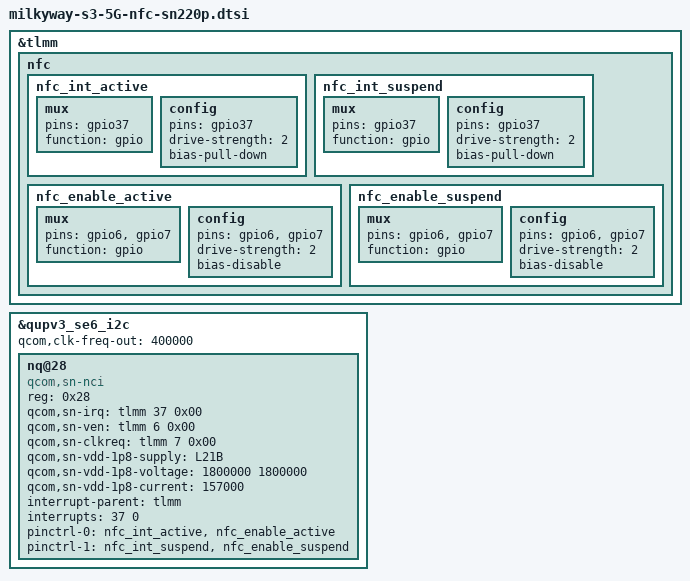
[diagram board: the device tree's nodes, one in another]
&tlmm {
	nfc {
		nfc_int_active: nfc_int_active {
			/* active state */
			mux {
				/* NFC Read Interrupt */
				pins = "gpio37";
				function = "gpio";
			};

			config {
				pins = "gpio37";
				drive-strength = <2>; /* 2 MA */
				bias-pull-down;
			};
		};

		nfc_int_suspend: nfc_int_suspend {
			/* sleep state */
			mux {
				/* NFC Read Interrupt */
				pins = "gpio37";
				function = "gpio";
			};

			config {
				pins = "gpio37";
				drive-strength = <2>; /* 2 MA */
				bias-pull-down;
			};
		};

		nfc_enable_active: nfc_enable_active {
			mux {
				/* Enable and Clock request gpios */
				pins = "gpio6", "gpio7";
				function = "gpio";
			};

			config {
				pins = "gpio6", "gpio7";
				drive-strength = <2>; /* 2 MA */
				bias-disable;
			};
		};

		nfc_enable_suspend: nfc_enable_suspend {
			mux {
				pins = "gpio6", "gpio7";
				function = "gpio";
			};

			config {
				pins = "gpio6", "gpio7";
				drive-strength = <2>; /* 2 MA */
				bias-disable;
			};
		};
	}; //nfc
}; //tlmm

&qupv3_se6_i2c {
	status = "ok";
	qcom,clk-freq-out = <400000>;
	#address-cells = <1>;
	#size-cells = <0>;
	nq@28 {
		compatible = "qcom,sn-nci";
		reg = <0x28>;
		qcom,sn-irq = <&tlmm 37 0x00>;
		qcom,sn-ven = <&tlmm 6 0x00>;
		qcom,sn-clkreq = <&tlmm 7 0x00>;
		qcom,sn-vdd-1p8-supply = <&L21B>;
		qcom,sn-vdd-1p8-voltage = <1800000 1800000>;
		qcom,sn-vdd-1p8-current = <157000>;
		interrupt-parent = <&tlmm>;
		interrupts = <37 0>;
		interrupt-names = "nfc_irq";
		pinctrl-names = "nfc_active", "nfc_suspend";
		pinctrl-0 = <&nfc_int_active &nfc_enable_active>;
		pinctrl-1 = <&nfc_int_suspend &nfc_enable_suspend>;
	};
};

